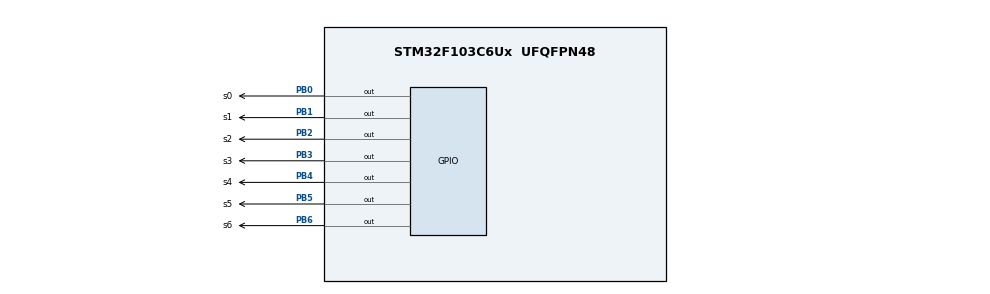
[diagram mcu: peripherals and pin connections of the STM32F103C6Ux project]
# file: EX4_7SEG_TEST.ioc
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Mcu.Family=STM32F1
Mcu.Name=STM32F103C6Ux
Mcu.Package=UFQFPN48
NVIC.PriorityGroup=NVIC_PRIORITYGROUP_4
PB0.GPIO_Label=s0
PB0.Signal=GPIO_Output
PB1.GPIO_Label=s1
PB1.Signal=GPIO_Output
PB2.GPIO_Label=s2
PB2.Signal=GPIO_Output
PB3.GPIO_Label=s3
PB3.Signal=GPIO_Output
PB4.GPIO_Label=s4
PB4.Signal=GPIO_Output
PB5.GPIO_Label=s5
PB5.Signal=GPIO_Output
PB6.GPIO_Label=s6
PB6.Signal=GPIO_Output
ProjectManager.HeapSize=0x200
ProjectManager.StackSize=0x400
ProjectManager.TargetToolchain=STM32CubeIDE
RCC.APB1Freq_Value=8000000
RCC.APB2Freq_Value=8000000
VP_SYS_VS_ND.Mode=No_Debug
board=custom

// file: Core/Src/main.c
/* USER CODE BEGIN Header */
/**
  ******************************************************************************
  * @file           : main.c
  * @brief          : Main program body
  ******************************************************************************
  * @attention
  *
  * <h2><center>&copy; Copyright (c) 2022 STMicroelectronics.
  * All rights reserved.</center></h2>
  *
  * This software component is licensed by ST under BSD 3-Clause license,
  * the "License"; You may not use this file except in compliance with the
  * License. You may obtain a copy of the License at:
  *                        opensource.org/licenses/BSD-3-Clause
  *
  ******************************************************************************
  */
/* USER CODE END Header */
#include "main.h"

void SystemClock_Config(void);
static void MX_GPIO_Init(void);

/* USER CODE BEGIN 0 */

uint8_t segmentArray[10] = {0x3f, 0x06, 0x5b, 0x4f, 0x66, 0x6d, 0x7d, 0x07, 0x7f, 0x6F}; //From 0 to 9

void display7SEG(int8_t counter) {
	if (counter<0 || counter>9) return;
	for (int i=0; i<7; i++) {
		HAL_GPIO_WritePin(s0_GPIO_Port, s0_Pin << i, !((segmentArray[counter]>>i)&0x1));
	}
}
/* USER CODE END 0 */

int main(void)
{

  /* MCU Configuration--------------------------------------------------------*/

  /* Reset of all peripherals, Initializes the Flash interface and the Systick. */
  HAL_Init();

  /* Configure the system clock */
  SystemClock_Config();

  /* Initialize all configured peripherals */
  MX_GPIO_Init();
  /* USER CODE BEGIN 2 */
  int8_t counter = 0;
  HAL_GPIO_WritePin(GPIOB, s0_Pin | s1_Pin | s2_Pin | s3_Pin | s4_Pin | s5_Pin | s6_Pin, GPIO_PIN_SET);
  /* USER CODE END 2 */

  /* Infinite loop */
  while (1)
  {

    /* USER CODE BEGIN 3 */
	  if (counter >= 10) counter = 0;
	  display7SEG(counter++);
	  HAL_Delay(1000);
  }
  /* USER CODE END 3 */
}

void SystemClock_Config(void)
{
  RCC_OscInitTypeDef RCC_OscInitStruct = {0};
  RCC_ClkInitTypeDef RCC_ClkInitStruct = {0};

  /** Initializes the RCC Oscillators according to the specified parameters
  * in the RCC_OscInitTypeDef structure.
  */
  RCC_OscInitStruct.OscillatorType = RCC_OSCILLATORTYPE_HSI;
  RCC_OscInitStruct.HSIState = RCC_HSI_ON;
  RCC_OscInitStruct.HSICalibrationValue = RCC_HSICALIBRATION_DEFAULT;
  RCC_OscInitStruct.PLL.PLLState = RCC_PLL_NONE;
  if (HAL_RCC_OscConfig(&RCC_OscInitStruct) != HAL_OK)
  {
    Error_Handler();
  }
  /** Initializes the CPU, AHB and APB buses clocks
  */
  RCC_ClkInitStruct.ClockType = RCC_CLOCKTYPE_HCLK|RCC_CLOCKTYPE_SYSCLK
                              |RCC_CLOCKTYPE_PCLK1|RCC_CLOCKTYPE_PCLK2;
  RCC_ClkInitStruct.SYSCLKSource = RCC_SYSCLKSOURCE_HSI;
  RCC_ClkInitStruct.AHBCLKDivider = RCC_SYSCLK_DIV1;
  RCC_ClkInitStruct.APB1CLKDivider = RCC_HCLK_DIV1;
  RCC_ClkInitStruct.APB2CLKDivider = RCC_HCLK_DIV1;

  if (HAL_RCC_ClockConfig(&RCC_ClkInitStruct, FLASH_LATENCY_0) != HAL_OK)
  {
    Error_Handler();
  }
}

static void MX_GPIO_Init(void)
{
  GPIO_InitTypeDef GPIO_InitStruct = {0};

  /* GPIO Ports Clock Enable */
  __HAL_RCC_GPIOB_CLK_ENABLE();

  /*Configure GPIO pin Output Level */
  HAL_GPIO_WritePin(GPIOB, s0_Pin|s1_Pin|s2_Pin|s3_Pin
                          |s4_Pin|s5_Pin|s6_Pin, GPIO_PIN_RESET);

  /*Configure GPIO pins : s0_Pin s1_Pin s2_Pin s3_Pin
                           s4_Pin s5_Pin s6_Pin */
  GPIO_InitStruct.Pin = s0_Pin|s1_Pin|s2_Pin|s3_Pin
                          |s4_Pin|s5_Pin|s6_Pin;
  GPIO_InitStruct.Mode = GPIO_MODE_OUTPUT_PP;
  GPIO_InitStruct.Pull = GPIO_NOPULL;
  GPIO_InitStruct.Speed = GPIO_SPEED_FREQ_LOW;
  HAL_GPIO_Init(GPIOB, &GPIO_InitStruct);

}

void Error_Handler(void)
{
  __disable_irq();
  while (1)
  {
  }
}

/************************ (C) COPYRIGHT STMicroelectronics *****END OF FILE****/
